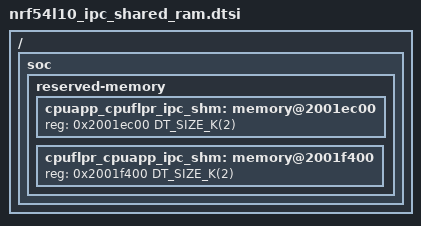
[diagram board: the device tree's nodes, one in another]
/*
 * Copyright (c) 2026 Nordic Semiconductor
 * SPDX-License-Identifier: Apache-2.0
 */

/ {
	soc {
		reserved-memory {
			#address-cells = <1>;
			#size-cells = <1>;

			cpuapp_cpuflpr_ipc_shm: memory@2001ec00 {
				reg = <0x2001ec00 DT_SIZE_K(2)>;
			};

			cpuflpr_cpuapp_ipc_shm: memory@2001f400 {
				reg = <0x2001f400 DT_SIZE_K(2)>;
			};
		};
	};
};
